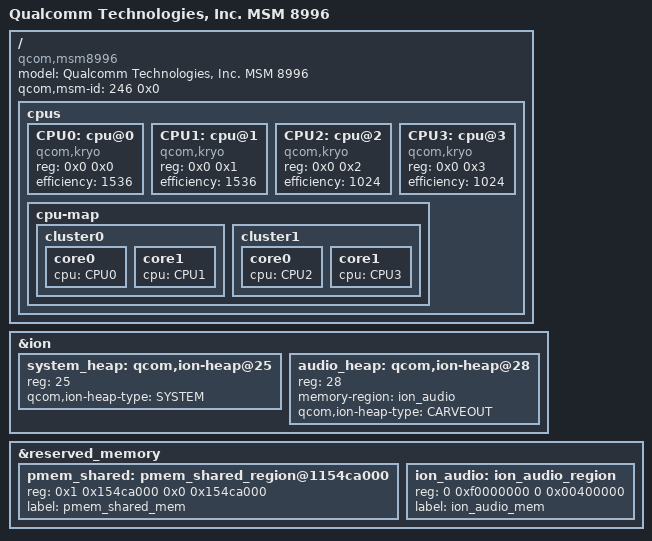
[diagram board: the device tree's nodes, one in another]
/* Copyright (c) 2017-2018, The Linux Foundation. All rights reserved.
 *
 * This program is free software; you can redistribute it and/or modify
 * it under the terms of the GNU General Public License version 2 and
 * only version 2 as published by the Free Software Foundation.
 *
 * This program is distributed in the hope that it will be useful,
 * but WITHOUT ANY WARRANTY; without even the implied warranty of
 * MERCHANTABILITY or FITNESS FOR A PARTICULAR PURPOSE.  See the
 * GNU General Public License for more details.
 */

/dts-v1/;

#include "vplatform-lfv-msm8996-ivi-common.dtsi"

/ {
	model = "Qualcomm Technologies, Inc. MSM 8996";
	compatible = "qcom,msm8996";
	qcom,msm-id = <246 0x0>;

	cpus {
		#address-cells = <2>;
		#size-cells = <0>;
		CPU0: cpu@0 {
			device_type = "cpu";
			compatible = "qcom,kryo";
			reg = <0x0 0x0>;
			efficiency = <1536>;
		};
		CPU1: cpu@1 {
			device_type = "cpu";
			compatible = "qcom,kryo";
			reg = <0x0 0x1>;
			efficiency = <1536>;
		};
		CPU2: cpu@2 {
			device_type = "cpu";
			compatible = "qcom,kryo";
			reg = <0x0 0x2>;
			efficiency = <1024>;
		};
		CPU3: cpu@3 {
			device_type = "cpu";
			compatible = "qcom,kryo";
			reg = <0x0 0x3>;
			efficiency = <1024>;
		};
		cpu-map {
			cluster0 {
				core0 {
					cpu = <&CPU0>;
				};
				core1 {
					cpu = <&CPU1>;
				};
			};

			cluster1 {
				core0 {
					cpu = <&CPU2>;
				};

				core1 {
					cpu = <&CPU3>;
				};
			};
		};
	};
};

&ion {
	/delete-node/ qcom,ion-heap@25;

	system_heap: qcom,ion-heap@25 {
		reg = <25>;
		qcom,ion-heap-type = "SYSTEM";
	};

	audio_heap: qcom,ion-heap@28 {
		reg = <28>;
		memory-region = <&ion_audio>;
		qcom,ion-heap-type = "CARVEOUT";
	};
};

&reserved_memory {
		pmem_shared: pmem_shared_region@1154ca000 {
			reg = <0x1 0x154ca000 0x0 0x154ca000>;
			label = "pmem_shared_mem";
		};

		ion_audio: ion_audio_region {
			reg = <0 0xf0000000 0 0x00400000>;
			label = "ion_audio_mem";
		};
};
